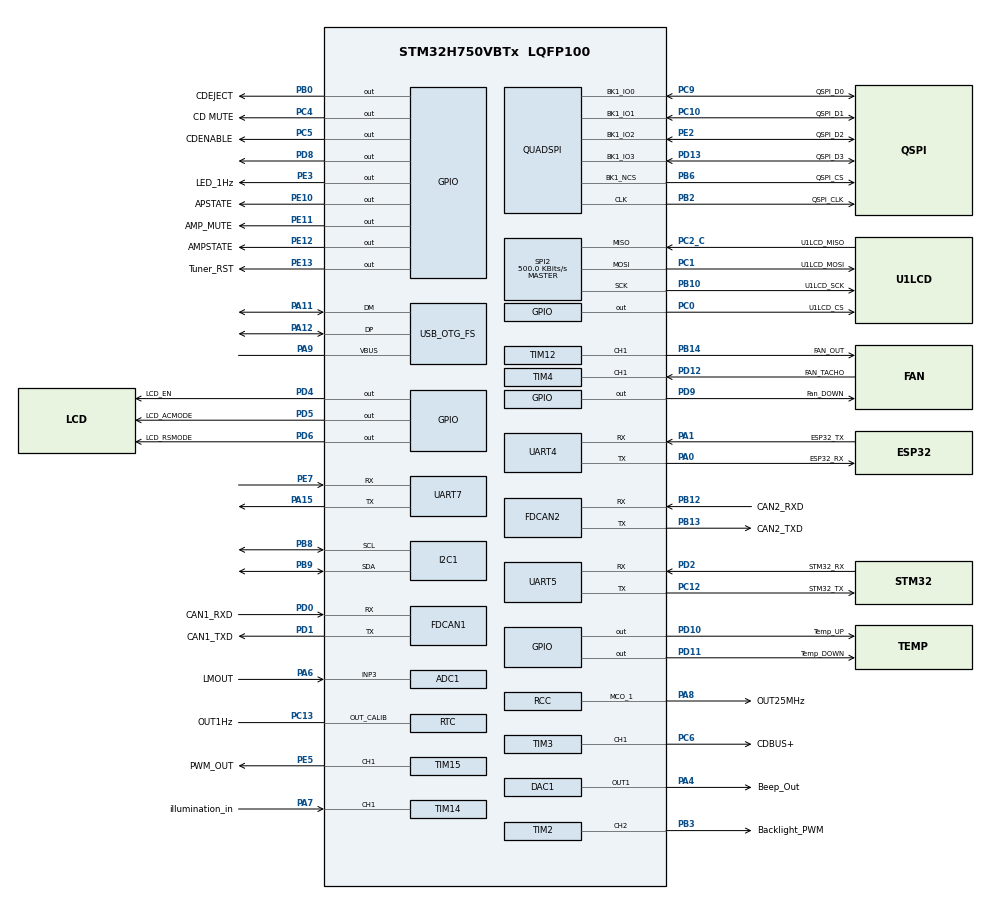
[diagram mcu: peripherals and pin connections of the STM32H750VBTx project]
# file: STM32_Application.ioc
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ADC1.Channel-1\#ChannelRegularConversion=ADC_CHANNEL_3
ADC1.NbrOfConversionFlag=1
ADC1.OffsetNumber-1\#ChannelRegularConversion=ADC_OFFSET_NONE
ADC1.OffsetSignedSaturation-1\#ChannelRegularConversion=DISABLE
ADC1.Rank-1\#ChannelRegularConversion=1
ADC1.SamplingTime-1\#ChannelRegularConversion=ADC_SAMPLETIME_1CYCLE_5
ADC1.master=1
CORTEX_M7.default_mode_Activation=1
DAC1.DAC_Channel-DAC_OUT1=DAC_CHANNEL_1
Dma.Request0=UART4_RX
Dma.Request1=UART5_RX
Dma.Request2=UART7_RX
Dma.UART4_RX.0.Direction=DMA_PERIPH_TO_MEMORY
Dma.UART4_RX.0.EventEnable=DISABLE
Dma.UART4_RX.0.FIFOMode=DMA_FIFOMODE_DISABLE
Dma.UART4_RX.0.Instance=DMA1_Stream0
Dma.UART4_RX.0.MemDataAlignment=DMA_MDATAALIGN_BYTE
Dma.UART4_RX.0.MemInc=DMA_MINC_ENABLE
Dma.UART4_RX.0.Mode=DMA_NORMAL
Dma.UART4_RX.0.PeriphDataAlignment=DMA_PDATAALIGN_BYTE
Dma.UART4_RX.0.PeriphInc=DMA_PINC_DISABLE
Dma.UART4_RX.0.Polarity=HAL_DMAMUX_REQ_GEN_RISING
Dma.UART4_RX.0.Priority=DMA_PRIORITY_LOW
Dma.UART4_RX.0.RequestNumber=1
Dma.UART4_RX.0.SignalID=NONE
Dma.UART4_RX.0.SyncEnable=DISABLE
Dma.UART4_RX.0.SyncPolarity=HAL_DMAMUX_SYNC_NO_EVENT
Dma.UART4_RX.0.SyncRequestNumber=1
Dma.UART4_RX.0.SyncSignalID=NONE
Dma.UART5_RX.1.Direction=DMA_PERIPH_TO_MEMORY
Dma.UART5_RX.1.EventEnable=DISABLE
Dma.UART5_RX.1.FIFOMode=DMA_FIFOMODE_DISABLE
Dma.UART5_RX.1.Instance=DMA1_Stream1
Dma.UART5_RX.1.MemDataAlignment=DMA_MDATAALIGN_BYTE
Dma.UART5_RX.1.MemInc=DMA_MINC_ENABLE
Dma.UART5_RX.1.Mode=DMA_NORMAL
Dma.UART5_RX.1.PeriphDataAlignment=DMA_PDATAALIGN_BYTE
Dma.UART5_RX.1.PeriphInc=DMA_PINC_DISABLE
Dma.UART5_RX.1.Polarity=HAL_DMAMUX_REQ_GEN_RISING
Dma.UART5_RX.1.Priority=DMA_PRIORITY_LOW
Dma.UART5_RX.1.RequestNumber=1
Dma.UART5_RX.1.SignalID=NONE
Dma.UART5_RX.1.SyncEnable=DISABLE
Dma.UART5_RX.1.SyncPolarity=HAL_DMAMUX_SYNC_NO_EVENT
Dma.UART5_RX.1.SyncRequestNumber=1
Dma.UART5_RX.1.SyncSignalID=NONE
Dma.UART7_RX.2.Direction=DMA_PERIPH_TO_MEMORY
Dma.UART7_RX.2.EventEnable=DISABLE
Dma.UART7_RX.2.FIFOMode=DMA_FIFOMODE_DISABLE
Dma.UART7_RX.2.Instance=DMA1_Stream2
Dma.UART7_RX.2.MemDataAlignment=DMA_MDATAALIGN_BYTE
Dma.UART7_RX.2.MemInc=DMA_MINC_ENABLE
Dma.UART7_RX.2.Mode=DMA_NORMAL
Dma.UART7_RX.2.PeriphDataAlignment=DMA_PDATAALIGN_BYTE
Dma.UART7_RX.2.PeriphInc=DMA_PINC_DISABLE
Dma.UART7_RX.2.Polarity=HAL_DMAMUX_REQ_GEN_RISING
Dma.UART7_RX.2.Priority=DMA_PRIORITY_LOW
Dma.UART7_RX.2.RequestNumber=1
Dma.UART7_RX.2.SignalID=NONE
Dma.UART7_RX.2.SyncEnable=DISABLE
Dma.UART7_RX.2.SyncPolarity=HAL_DMAMUX_SYNC_NO_EVENT
Dma.UART7_RX.2.SyncRequestNumber=1
Dma.UART7_RX.2.SyncSignalID=NONE
FDCAN1.CalculateBaudRateNominal=500000
FDCAN1.CalculateTimeBitNominal=2000
FDCAN1.CalculateTimeQuantumNominal=200.0
FDCAN1.NominalPrescaler=5
FDCAN1.NominalTimeSeg1=7
FDCAN1.NominalTimeSeg2=2
FDCAN1.TxFifoQueueElmtsNbr=32
FDCAN2.CalculateBaudRateNominal=500000
FDCAN2.CalculateTimeBitNominal=2000
FDCAN2.CalculateTimeQuantumNominal=200.0
FDCAN2.NominalPrescaler=5
FDCAN2.NominalTimeSeg1=7
FDCAN2.NominalTimeSeg2=2
FDCAN2.TxFifoQueueElmtsNbr=32
I2C1.Timing=0x00C0EAFF
Mcu.Family=STM32H7
Mcu.Name=STM32H750VBTx
Mcu.Package=LQFP100
NVIC.DMA1_Stream0_IRQn=true\:0\:0\:false\:false\:true\:false\:true\:true
NVIC.DMA1_Stream1_IRQn=true\:0\:0\:false\:false\:true\:false\:true\:true
NVIC.DMA1_Stream2_IRQn=true\:0\:0\:false\:false\:true\:false\:true\:true
NVIC.OTG_FS_IRQn=true\:0\:0\:false\:false\:true\:false\:true\:true
NVIC.PriorityGroup=NVIC_PRIORITYGROUP_4
NVIC.TIM3_IRQn=true\:0\:0\:false\:false\:true\:true\:true\:true
NVIC.UART4_IRQn=true\:0\:0\:false\:false\:true\:true\:true\:true
NVIC.UART7_IRQn=true\:0\:0\:false\:false\:true\:true\:true\:true
PA0.GPIO_Label=ESP32_RX
PA0.Mode=Asynchronous
PA0.Signal=UART4_TX
PA1.GPIO_Label=ESP32_TX
PA1.Mode=Asynchronous
PA1.Signal=UART4_RX
PA11.Mode=Device_Only
PA11.PinAttribute=Free
PA11.Signal=USB_OTG_FS_DM
PA12.Mode=Device_Only
PA12.PinAttribute=Free
PA12.Signal=USB_OTG_FS_DP
PA13\ (JTMS/SWDIO).Mode=Serial_Wire
PA13\ (JTMS/SWDIO).Signal=DEBUG_JTMS-SWDIO
PA14\ (JTCK/SWCLK).Mode=Serial_Wire
PA14\ (JTCK/SWCLK).Signal=DEBUG_JTCK-SWCLK
PA15\ (JTDI).Mode=Asynchronous
PA15\ (JTDI).PinAttribute=Free
PA15\ (JTDI).Signal=UART7_TX
PA4.GPIO_Label=Beep_Out
PA4.Signal=COMP_DAC11_group
PA6.GPIO_Label=LMOUT
PA6.Signal=ADCx_INP3
PA7.GPIO_Label=illumination_in
PA7.PinAttribute=Free
PA7.Signal=S_TIM14_CH1
PA8.GPIO_Label=OUT25MHz
PA8.Mode=Clock-out-1
PA8.PinAttribute=Free
PA8.Signal=RCC_MCO_1
PA9.Mode=Activate_VBUS
PA9.PinAttribute=Free
PA9.Signal=USB_OTG_FS_VBUS
PB0.GPIO_Label=CDEJECT
PB0.PinAttribute=Free
PB0.Signal=GPIO_Output
PB10.GPIO_Label=U1LCD_SCK
PB10.Mode=Full_Duplex_Master
PB10.Signal=SPI2_SCK
PB12.GPIO_Label=CAN2_RXD
PB12.Mode=FDCAN_Activate
PB12.Signal=FDCAN2_RX
PB13.GPIO_Label=CAN2_TXD
PB13.Mode=FDCAN_Activate
PB13.Signal=FDCAN2_TX
PB14.GPIO_Label=FAN_OUT
PB14.Signal=S_TIM12_CH1
PB2.GPIO_Label=QSPI_CLK
PB2.Mode=Single Bank 1
PB2.PinAttribute=Free
PB2.Signal=QUADSPI_CLK
PB3\ (JTDO/TRACESWO).GPIO_Label=Backlight_PWM
PB3\ (JTDO/TRACESWO).PinAttribute=Free
PB3\ (JTDO/TRACESWO).Signal=S_TIM2_CH2
PB6.GPIO_Label=QSPI_CS
PB6.Mode=Single Bank 1
PB6.Signal=QUADSPI_BK1_NCS
PB8.Mode=I2C
PB8.Signal=I2C1_SCL
PB9.Mode=I2C
PB9.Signal=I2C1_SDA
PC0.GPIO_Label=U1LCD_CS
PC0.Signal=GPIO_Output
PC1.GPIO_Label=U1LCD_MOSI
PC1.Mode=Full_Duplex_Master
PC1.Signal=SPI2_MOSI
PC10.GPIO_Label=QSPI_D1
PC10.Mode=Single Bank 1
PC10.PinAttribute=Free
PC10.Signal=QUADSPI_BK1_IO1
PC12.GPIO_Label=STM32_TX
PC12.Mode=Asynchronous
PC12.PinAttribute=Free
PC12.Signal=UART5_TX
PC13.GPIO_Label=OUT1Hz
PC13.Mode=Calibration_1Hz
PC13.Signal=RTC_OUT_CALIB
PC14-OSC32_IN\ (OSC32_IN).Mode=LSE-External-Oscillator
PC14-OSC32_IN\ (OSC32_IN).Signal=RCC_OSC32_IN
PC15-OSC32_OUT\ (OSC32_OUT).Mode=LSE-External-Oscillator
PC15-OSC32_OUT\ (OSC32_OUT).Signal=RCC_OSC32_OUT
PC2_C.GPIO_Label=U1LCD_MISO
PC2_C.Mode=Full_Duplex_Master
PC2_C.Signal=SPI2_MISO
PC3_C.GPIO_Label=WheelButtonIN
PC3_C.Signal=ADC3_INP1
PC4.GPIO_Label=CD MUTE
PC4.PinAttribute=Free
PC4.Signal=GPIO_Output
PC5.GPIO_Label=CDENABLE
PC5.PinAttribute=Free
PC5.Signal=GPIO_Output
PC6.GPIO_Label=CDBUS+
PC6.Signal=S_TIM3_CH1
PC9.GPIO_Label=QSPI_D0
PC9.Mode=Single Bank 1
PC9.Signal=QUADSPI_BK1_IO0
PD0.GPIO_Label=CAN1_RXD
PD0.Mode=FDCAN_Activate
PD0.PinAttribute=Free
PD0.Signal=FDCAN1_RX
PD1.GPIO_Label=CAN1_TXD
PD1.Mode=FDCAN_Activate
PD1.PinAttribute=Free
PD1.Signal=FDCAN1_TX
PD10.GPIO_Label=Temp_UP
PD10.Signal=GPIO_Output
PD11.GPIO_Label=Temp_DOWN
PD11.Signal=GPIO_Output
PD12.GPIO_Label=FAN_TACHO
PD12.Signal=S_TIM4_CH1
PD13.GPIO_Label=QSPI_D3
PD13.Mode=Single Bank 1
PD13.Signal=QUADSPI_BK1_IO3
PD2.GPIO_Label=STM32_RX
PD2.Mode=Asynchronous
PD2.PinAttribute=Free
PD2.Signal=UART5_RX
PD4.GPIO_Label=LCD_EN
PD4.PinAttribute=Free
PD4.Signal=GPIO_Output
PD5.GPIO_Label=LCD_ACMODE
PD5.PinAttribute=Free
PD5.Signal=GPIO_Output
PD6.GPIO_Label=LCD_RSMODE
PD6.PinAttribute=Free
PD6.Signal=GPIO_Output
PD8.Signal=GPIO_Output
PD9.GPIO_Label=Fan_DOWN
PD9.Signal=GPIO_Output
PE10.GPIO_Label=APSTATE
PE10.Signal=GPIO_Output
PE11.GPIO_Label=AMP_MUTE
PE11.Signal=GPIO_Output
PE12.GPIO_Label=AMPSTATE
PE12.Signal=GPIO_Output
PE13.GPIO_Label=Tuner_RST
PE13.Signal=GPIO_Output
PE2.GPIO_Label=QSPI_D2
PE2.Mode=Single Bank 1
PE2.Signal=QUADSPI_BK1_IO2
PE3.GPIO_Label=LED_1Hz
PE3.Signal=GPIO_Output
PE5.GPIO_Label=PWM_OUT
PE5.Signal=S_TIM15_CH1
PE7.Mode=Asynchronous
PE7.Signal=UART7_RX
PH0-OSC_IN\ (PH0).Mode=HSE-External-Oscillator
PH0-OSC_IN\ (PH0).Signal=RCC_OSC_IN
PH1-OSC_OUT\ (PH1).Mode=HSE-External-Oscillator
PH1-OSC_OUT\ (PH1).Signal=RCC_OSC_OUT
ProjectManager.HeapSize=0x200
ProjectManager.StackSize=0x400
ProjectManager.TargetToolchain=STM32CubeIDE
RCC.ADCFreq_Value=75000000
RCC.APB1Freq_Value=50000000
RCC.APB2Freq_Value=100000000
RCC.APB3Freq_Value=100000000
RCC.APB4Freq_Value=100000000
RCC.CortexFreq_Value=400000000
RCC.D1PPRE=RCC_APB3_DIV2
RCC.D2PPRE1=RCC_APB1_DIV4
RCC.D2PPRE2=RCC_APB2_DIV2
RCC.D3PPRE=RCC_APB4_DIV2
RCC.DIVM1=2
RCC.DIVM2=2
RCC.DIVN1=64
RCC.DIVN2=12
RCC.DIVQ1=3
RCC.EnbaleCSS=false
RCC.FDCANCLockSelection=RCC_FDCANCLKSOURCE_HSE
RCC.FLatency-AdvancedSettings=FLASH_LATENCY_0
RCC.HCLKFreq_Value=200000000
RCC.HPRE=RCC_HCLK_DIV2
RCC.PLL1_VCI_Range-AdvancedSettings=RCC_PLL1VCIRANGE_0
RCC.PLL1_VCO_SEL-AdvancedSettings=RCC_PLL1VCOMEDIUM
RCC.PLL2FRACN=0
RCC.PLL2_VCI_Range-AdvancedSettings=RCC_PLL2VCIRANGE_0
RCC.PLL2_VCO_SEL-AdvancedSettings=RCC_PLL2VCOWIDE
RCC.PLL3FRACN=0
RCC.PLL3_VCI_Range-AdvancedSettings=RCC_PLL3VCIRANGE_0
RCC.PLL3_VCO_SEL-AdvancedSettings=RCC_PLL3VCOMEDIUM
RCC.PLLFRACN=0
RCC.PLLSourceVirtual=RCC_PLLSOURCE_HSE
RCC.PWR_Regulator_Voltage_Scale=PWR_REGULATOR_VOLTAGE_SCALE1
RCC.QSPICLockSelection=RCC_QSPICLKSOURCE_PLL2
RCC.SPI123CLockSelection=RCC_SPI123CLKSOURCE_CLKP
RCC.SYSCLKFreq_VALUE=400000000
RCC.SYSCLKSource=RCC_SYSCLKSOURCE_PLLCLK
RCC.Tim2Mul=1
RCC.USBCLockSelection=RCC_USBCLKSOURCE_HSI48
RCC.USBFreq_Value=48000000
SH.ADCx_INP3.0=ADC2_INP3
SH.ADCx_INP3.1=ADC1_INP3,IN3-Single-Ended
SH.COMP_DAC11_group.0=DAC1_OUT1,DAC_OUT1
SH.S_TIM12_CH1.0=TIM12_CH1,PWM Generation1 CH1
SH.S_TIM14_CH1.0=TIM14_CH1,Input_Capture1_from_TI1
SH.S_TIM15_CH1.0=TIM15_CH1,PWM Generation1 CH1
SH.S_TIM2_CH2.0=TIM2_CH2,PWM Generation2 CH2
SH.S_TIM3_CH1.0=TIM3_CH1,Output Compare1 CH1
SH.S_TIM4_CH1.0=TIM4_CH1,Input_Capture1_from_TI1
SPI2.BaudRatePrescaler=SPI_BAUDRATEPRESCALER_128
SPI2.CLKPhase=SPI_PHASE_2EDGE
SPI2.CLKPolarity=SPI_POLARITY_HIGH
SPI2.CalculateBaudRate=500.0 KBits/s
SPI2.Direction=SPI_DIRECTION_2LINES
SPI2.Mode=SPI_MODE_MASTER
SPI2.NSSPMode=SPI_NSS_PULSE_DISABLE
SPI2.VirtualType=VM_MASTER
TIM12.Channel-PWM\ Generation1\ CH1=TIM_CHANNEL_1
TIM14.Channel=TIM_CHANNEL_1
TIM15.Channel-PWM\ Generation1\ CH1=TIM_CHANNEL_1
TIM2.Channel-PWM\ Generation2\ CH2=TIM_CHANNEL_2
TIM3.AutoReloadPreload=TIM_AUTORELOAD_PRELOAD_ENABLE
TIM3.Channel-Output\ Compare1\ CH1=TIM_CHANNEL_1
TIM3.OC1Preload=ENABLE
TIM3.OCMode_1=TIM_OCMODE_ACTIVE
TIM4.Channel-Input_Capture1_from_TI1=TIM_CHANNEL_1
TIM6.TIM_MasterOutputTrigger=TIM_TRGO_UPDATE
USB_DEVICE.CLASS_NAME_FS=CDC
USB_DEVICE.VirtualMode-CDC_FS=Cdc
USB_DEVICE.VirtualModeFS=Cdc_FS
USB_OTG_FS.VirtualMode=Device_Only
VP_MEMORYMAP_VS_MEMORYMAP.Mode=CurAppReg
VP_RTC_VS_RTC_Activate.Mode=RTC_Enabled
VP_TIM12_VS_ClockSourceINT.Mode=Internal
VP_TIM14_VS_ClockSourceINT.Mode=Enable_Timer
VP_TIM15_VS_ClockSourceINT.Mode=Internal
VP_TIM2_VS_ClockSourceINT.Mode=Internal
VP_TIM4_VS_ClockSourceINT.Mode=Internal
VP_TIM6_VS_ClockSourceINT.Mode=Enable_Timer
VP_USB_DEVICE_VS_USB_DEVICE_CDC_FS.Mode=CDC_FS
board=custom

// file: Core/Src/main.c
/* USER CODE BEGIN Header */
/**
  ******************************************************************************
  * @file           : main.c
  * @brief          : Main program body
  ******************************************************************************
  * @attention
  *
  * Copyright (c) 2026 STMicroelectronics.
  * All rights reserved.
  *
  * This software is licensed under terms that can be found in the LICENSE file
  * in the root directory of this software component.
  * If no LICENSE file comes with this software, it is provided AS-IS.
  *
  ******************************************************************************
  */
/* USER CODE END Header */
#include "main.h"
#include "usb_device.h"

/* USER CODE BEGIN Includes */
#include <string.h>
#include "usbd_cdc_if.h"

//Communication folder
#include "communication/protocol.h"
#include "communication/canbus.h"
#include "communication/lcd.h"
#include "communication/climate.h"

//drivers folder
#include "drivers/lm75.h"
#include "drivers/si4703.h"
#include "drivers/tda7719.h"

//vehicle folder
#include "vehicle/audio.h"
#include "vehicle/time.h"
#include "vehicle/lighting.h"

/* USER CODE END Includes */

ADC_HandleTypeDef hadc1;

DAC_HandleTypeDef hdac1;

FDCAN_HandleTypeDef hfdcan1;
FDCAN_HandleTypeDef hfdcan2;

I2C_HandleTypeDef hi2c1;

QSPI_HandleTypeDef hqspi;

RTC_HandleTypeDef hrtc;

SPI_HandleTypeDef hspi2;

TIM_HandleTypeDef htim2;
TIM_HandleTypeDef htim3;
TIM_HandleTypeDef htim4;
TIM_HandleTypeDef htim6;
TIM_HandleTypeDef htim12;
TIM_HandleTypeDef htim14;
TIM_HandleTypeDef htim15;

UART_HandleTypeDef huart4;
UART_HandleTypeDef huart5;
UART_HandleTypeDef huart7;
DMA_HandleTypeDef hdma_uart4_rx;
DMA_HandleTypeDef hdma_uart5_rx;
DMA_HandleTypeDef hdma_uart7_rx;

/* USER CODE BEGIN PV */
uint32_t lastClimateSend = 0;
uint32_t lastFanSend = 0;
volatile uint8_t uart7ErrorFlag = 0;
volatile uint32_t uart7ErrorCode = 0;
int uart7RxCount = 0;

int uart5RxCount = 0;
uint32_t uart7LastSize;
RTC_TimeTypeDef sTime = {0};
RTC_DateTypeDef sDate = {0};
uint8_t lastMinute = 60; //not possible
volatile uint8_t minuteChanged = 1; // Start at 1 to update LCD on boot
uint8_t volumePending = 0;
uint8_t lastVolume = 0;
uint8_t volumeChange = 0;
uint8_t lcdReset = 0;
uint32_t lcdResetTimer = 0;
char lastLCDMessage[13] = "Welcome :)   "; //Init to welcome as standard
extern char lcdBuf[13];
extern ACState_t acState;
/* USER CODE END PV */

void SystemClock_Config(void);
void PeriphCommonClock_Config(void);
static void MPU_Config(void);
static void MX_GPIO_Init(void);
static void MX_DMA_Init(void);
static void MX_ADC1_Init(void);
static void MX_DAC1_Init(void);
static void MX_FDCAN1_Init(void);
static void MX_FDCAN2_Init(void);
static void MX_RTC_Init(void);
static void MX_SPI2_Init(void);
static void MX_TIM2_Init(void);
static void MX_TIM6_Init(void);
static void MX_TIM15_Init(void);
static void MX_UART4_Init(void);
static void MX_UART5_Init(void);
static void MX_UART7_Init(void);
static void MX_TIM4_Init(void);
static void MX_TIM12_Init(void);
static void MX_QUADSPI_Init(void);
static void MX_TIM14_Init(void);
static void MX_TIM3_Init(void);
static void MX_I2C1_Init(void);
/* USER CODE BEGIN PFP */
void Report_USB(const char* text);
void I2C_Scan(I2C_HandleTypeDef *hi2c);
void Startup_Handshake();
/* USER CODE END PFP */

int main(void)
{

  /* USER CODE BEGIN 1 */
	uint32_t pre_P1R = RTC->BKP1R;

  /* USER CODE END 1 */

  /* MPU Configuration--------------------------------------------------------*/
  MPU_Config();

  /* MCU Configuration--------------------------------------------------------*/

  /* Reset of all peripherals, Initializes the Flash interface and the Systick. */
  HAL_Init();

  /* Configure the system clock */
  SystemClock_Config();

  /* Configure the peripherals common clocks */
  PeriphCommonClock_Config();

  /* Initialize all configured peripherals */
  MX_GPIO_Init();
  MX_DMA_Init();
  MX_ADC1_Init();
  MX_DAC1_Init();
  MX_FDCAN1_Init();
  MX_FDCAN2_Init();
  MX_RTC_Init();
  MX_SPI2_Init();
  MX_TIM2_Init();
  MX_TIM6_Init();
  MX_TIM15_Init();
  MX_UART4_Init();
  MX_UART5_Init();
  MX_UART7_Init();
  MX_USB_DEVICE_Init();
  MX_TIM4_Init();
  MX_TIM12_Init();
  MX_QUADSPI_Init();
  MX_TIM14_Init();
  MX_TIM3_Init();
  MX_I2C1_Init();

  HAL_PWR_EnableBkUpAccess();
  char buf[240];
  if (pre_P1R == 0x0000){
	  snprintf(buf, sizeof(buf),
		  "COLD: TR=0x%08lX DR=0x%08lX BKP1=0x%08lX BKP1_R=0x%08lX BDCR=0x%08lX BKP1R=0x%08lX BKP0R=0x%08lX",
		  RTC->TR, RTC->DR, RTC->BKP1R, pre_P1R, RCC->BDCR,  RTC->BKP1R, RTC->BKP0R);
  }
  else{
	  snprintf(buf, sizeof(buf),
		  "HOT: TR=0x%08lX DR=0x%08lX BKP1=0x%08lX BKP1_R=0x%08lX BDCR=0x%08lX BKP1R=0x%08lX BKP0R=0x%08lX",
		  RTC->TR, RTC->DR, RTC->BKP1R, pre_P1R, RCC->BDCR,  RTC->BKP1R, RTC->BKP0R);
  }
  HAL_Delay(1000);
  DWT_Init();
  TDA7719_Init(&hi2c1);
  //Report_USB("Booting...");
  LCD_Init(&hspi2, &htim2);
  Climate_Init(&huart7);
  LCD_Print("Booting...");

  CAN_Start(&hfdcan1, &hfdcan2);

  HAL_UARTEx_ReceiveToIdle_DMA(&huart4, RxBuf4, RX_PACKET_LEN);
  HAL_UARTEx_ReceiveToIdle_DMA(&huart5, RxBuf5, RX_PACKET_LEN);
  //Protocol_Send(&huart4, STM, CMD_HANDSHAKE, NULL, 0);
  Startup_Handshake();

  //Climate_SendStatus(&huart5);
  //HAL_Delay(1000);

  //LM75_Init(&hi2c2);
  // Basic temperature read
  //float temp = LM75_ReadTemp();

  /* USER CODE END 2 */

  /* Infinite loop */
  /* USER CODE BEGIN WHILE */
  //I2C_Scan(&hi2c1);
  int counter = 0;
  int lastCANsend = HAL_GetTick();
  uint32_t lastPrint = 0;

  Audio_Init();
  LCD_Print("Loop Starting...");
  HAL_Delay(100);
  Report_USB(buf);
  HAL_Delay(1000);

  while (1)
  {
      counter++;
      Protocol_CheckFlag(&huart4, &huart5);
      Climate_CheckFlag();
      CAN_CheckFlag();

      HAL_RTC_GetTime(&hrtc, &sTime, RTC_FORMAT_BIN);
      HAL_RTC_GetDate(&hrtc, &sDate, RTC_FORMAT_BIN); // CRITICAL: You MUST read the date after the time

      if (sTime.Minutes != lastMinute) {
    	  Report_USB("Minute Changed");
          Climate_SetLCD(&acState);
          lastMinute = sTime.Minutes; // Save the new minute
      }

      if (lcdReset && (HAL_GetTick() - lcdResetTimer >= 3000)){
			  //reset LCD to the last known buffer
			  LCD_Print(lastLCDMessage);
			  lcdReset = 0;
      }

      if (HAL_GetTick() - lastCANsend >= 1000) {
    	  //Send CAN frame every second to test CAN2.
          uint8_t data[8] = {0x11, 0x22, 0x33, 0x44, 0x55, 0x66, 0x77, 0x88};
          CAN_Send(data, 0x123);

          FDCAN_ProtocolStatusTypeDef psr;
          HAL_FDCAN_GetProtocolStatus(&hfdcan2, &psr);

          char dbg[128];
          lastCANsend = HAL_GetTick();
          FDCAN_ProtocolStatusTypeDef psr1;
          HAL_FDCAN_GetProtocolStatus(&hfdcan1, &psr1);
      }

      if (HAL_GetTick() - lastPrint > 20)
      {
          lastPrint = HAL_GetTick();
          Climate_SendDefault();
      }

  }
      /* USER CODE END WHILE */

}
    /* Use this when LSE is working...
     *
     */
    void SystemClock_Config(void)
    {
      RCC_OscInitTypeDef RCC_OscInitStruct = {0};
      RCC_ClkInitTypeDef RCC_ClkInitStruct = {0};

      // Supply configuration update enable
      HAL_PWREx_ConfigSupply(PWR_LDO_SUPPLY);

      // Configure the main internal regulator output voltage
      __HAL_PWR_VOLTAGESCALING_CONFIG(PWR_REGULATOR_VOLTAGE_SCALE1);

      while(!__HAL_PWR_GET_FLAG(PWR_FLAG_VOSRDY)) {}

      // Configure LSE Drive Capability
      HAL_PWR_EnableBkUpAccess();

	// *** TEMPORARY CODE TO CLEAR STUCK LSI SETTING ***
	//__HAL_RCC_BACKUPRESET_FORCE();
	//__HAL_RCC_BACKUPRESET_RELEASE();
	// *************************************************

      __HAL_RCC_LSEDRIVE_CONFIG(RCC_LSEDRIVE_HIGH);

      // Initializes the RCC Oscillators according to the specified parameters
      //in the RCC_OscInitTypeDef structure.

      RCC_OscInitStruct.OscillatorType = RCC_OSCILLATORTYPE_HSI48|RCC_OSCILLATORTYPE_HSI
                                  |RCC_OSCILLATORTYPE_HSE|RCC_OSCILLATORTYPE_LSE;
      RCC_OscInitStruct.HSEState = RCC_HSE_ON;
      RCC_OscInitStruct.LSEState = RCC_LSE_ON;
      RCC_OscInitStruct.HSIState = RCC_HSI_DIV1;
      RCC_OscInitStruct.HSICalibrationValue = RCC_HSICALIBRATION_DEFAULT;
      RCC_OscInitStruct.HSI48State = RCC_HSI48_ON;
      RCC_OscInitStruct.PLL.PLLState = RCC_PLL_ON;
      RCC_OscInitStruct.PLL.PLLSource = RCC_PLLSOURCE_HSE;
      RCC_OscInitStruct.PLL.PLLM = 2;
      RCC_OscInitStruct.PLL.PLLN = 64;
      RCC_OscInitStruct.PLL.PLLP = 2;
      RCC_OscInitStruct.PLL.PLLQ = 3;
      RCC_OscInitStruct.PLL.PLLR = 2;
      RCC_OscInitStruct.PLL.PLLRGE = RCC_PLL1VCIRANGE_3;
      RCC_OscInitStruct.PLL.PLLVCOSEL = RCC_PLL1VCOWIDE;
      RCC_OscInitStruct.PLL.PLLFRACN = 0;
      if (HAL_RCC_OscConfig(&RCC_OscInitStruct) != HAL_OK)
      {
        Error_Handler();
      }

      if (__HAL_RCC_GET_FLAG(RCC_FLAG_LSERDY) == RESET) {
          uint32_t timeout = HAL_GetTick();
          while (__HAL_RCC_GET_FLAG(RCC_FLAG_LSERDY) == RESET) {
              if (HAL_GetTick() - timeout > 2000) {
                  Error_Handler(); // or fallback to LSI
              }
          }
      }

      // Initializes the CPU, AHB and APB buses clocks

      RCC_ClkInitStruct.ClockType = RCC_CLOCKTYPE_HCLK|RCC_CLOCKTYPE_SYSCLK
                                  |RCC_CLOCKTYPE_PCLK1|RCC_CLOCKTYPE_PCLK2
                                  |RCC_CLOCKTYPE_D3PCLK1|RCC_CLOCKTYPE_D1PCLK1;
      RCC_ClkInitStruct.SYSCLKSource = RCC_SYSCLKSOURCE_PLLCLK;
      RCC_ClkInitStruct.SYSCLKDivider = RCC_SYSCLK_DIV1;
      RCC_ClkInitStruct.AHBCLKDivider = RCC_HCLK_DIV2;
      RCC_ClkInitStruct.APB3CLKDivider = RCC_APB3_DIV2;
      RCC_ClkInitStruct.APB1CLKDivider = RCC_APB1_DIV4;
      RCC_ClkInitStruct.APB2CLKDivider = RCC_APB2_DIV2;
      RCC_ClkInitStruct.APB4CLKDivider = RCC_APB4_DIV2;

      RCC_PeriphCLKInitTypeDef PeriphClkInitStruct = {0};

      if (HAL_RCC_ClockConfig(&RCC_ClkInitStruct, FLASH_LATENCY_2) != HAL_OK)
      {
        Error_Handler();
      }

      // Route the LSE to the RTC block
      PeriphClkInitStruct.PeriphClockSelection = RCC_PERIPHCLK_RTC;
      PeriphClkInitStruct.RTCClockSelection = RCC_RTCCLKSOURCE_LSE;
      if (HAL_RCCEx_PeriphCLKConfig(&PeriphClkInitStruct) != HAL_OK)
      {
        Error_Handler();
      }

      HAL_RCC_MCOConfig(RCC_MCO1, RCC_MCO1SOURCE_LSE, RCC_MCODIV_1);
      //Change to HSE for 25MHz
  }

void PeriphCommonClock_Config(void)
{
  RCC_PeriphCLKInitTypeDef PeriphClkInitStruct = {0};

  /** Initializes the peripherals clock
  */
  PeriphClkInitStruct.PeriphClockSelection = RCC_PERIPHCLK_QSPI|RCC_PERIPHCLK_ADC
                              |RCC_PERIPHCLK_CKPER;
  PeriphClkInitStruct.PLL2.PLL2M = 2;
  PeriphClkInitStruct.PLL2.PLL2N = 12;
  PeriphClkInitStruct.PLL2.PLL2P = 2;
  PeriphClkInitStruct.PLL2.PLL2Q = 2;
  PeriphClkInitStruct.PLL2.PLL2R = 2;
  PeriphClkInitStruct.PLL2.PLL2RGE = RCC_PLL2VCIRANGE_3;
  PeriphClkInitStruct.PLL2.PLL2VCOSEL = RCC_PLL2VCOMEDIUM;
  PeriphClkInitStruct.PLL2.PLL2FRACN = 0;
  PeriphClkInitStruct.QspiClockSelection = RCC_QSPICLKSOURCE_PLL2;
  PeriphClkInitStruct.CkperClockSelection = RCC_CLKPSOURCE_HSI;
  PeriphClkInitStruct.AdcClockSelection = RCC_ADCCLKSOURCE_PLL2;
  if (HAL_RCCEx_PeriphCLKConfig(&PeriphClkInitStruct) != HAL_OK)
  {
    Error_Handler();
  }
}

static void MX_ADC1_Init(void)
{

  ADC_MultiModeTypeDef multimode = {0};
  ADC_ChannelConfTypeDef sConfig = {0};

  /** Common config
  */
  hadc1.Instance = ADC1;
  hadc1.Init.ClockPrescaler = ADC_CLOCK_ASYNC_DIV1;
  hadc1.Init.Resolution = ADC_RESOLUTION_16B;
  hadc1.Init.ScanConvMode = ADC_SCAN_DISABLE;
  hadc1.Init.EOCSelection = ADC_EOC_SINGLE_CONV;
  hadc1.Init.LowPowerAutoWait = DISABLE;
  hadc1.Init.ContinuousConvMode = DISABLE;
  hadc1.Init.NbrOfConversion = 1;
  hadc1.Init.DiscontinuousConvMode = DISABLE;
  hadc1.Init.ExternalTrigConv = ADC_SOFTWARE_START;
  hadc1.Init.ExternalTrigConvEdge = ADC_EXTERNALTRIGCONVEDGE_NONE;
  hadc1.Init.ConversionDataManagement = ADC_CONVERSIONDATA_DR;
  hadc1.Init.Overrun = ADC_OVR_DATA_PRESERVED;
  hadc1.Init.LeftBitShift = ADC_LEFTBITSHIFT_NONE;
  hadc1.Init.OversamplingMode = DISABLE;
  hadc1.Init.Oversampling.Ratio = 1;
  if (HAL_ADC_Init(&hadc1) != HAL_OK)
  {
    Error_Handler();
  }

  /** Configure the ADC multi-mode
  */
  multimode.Mode = ADC_MODE_INDEPENDENT;
  if (HAL_ADCEx_MultiModeConfigChannel(&hadc1, &multimode) != HAL_OK)
  {
    Error_Handler();
  }

  /** Configure Regular Channel
  */
  sConfig.Channel = ADC_CHANNEL_3;
  sConfig.Rank = ADC_REGULAR_RANK_1;
  sConfig.SamplingTime = ADC_SAMPLETIME_1CYCLE_5;
  sConfig.SingleDiff = ADC_SINGLE_ENDED;
  sConfig.OffsetNumber = ADC_OFFSET_NONE;
  sConfig.Offset = 0;
  sConfig.OffsetSignedSaturation = DISABLE;
  if (HAL_ADC_ConfigChannel(&hadc1, &sConfig) != HAL_OK)
  {
    Error_Handler();
  }

}

static void MX_DAC1_Init(void)
{

  DAC_ChannelConfTypeDef sConfig = {0};

  /** DAC Initialization
  */
  hdac1.Instance = DAC1;
  if (HAL_DAC_Init(&hdac1) != HAL_OK)
  {
    Error_Handler();
  }

  /** DAC channel OUT1 config
  */
  sConfig.DAC_SampleAndHold = DAC_SAMPLEANDHOLD_DISABLE;
  sConfig.DAC_Trigger = DAC_TRIGGER_NONE;
  sConfig.DAC_OutputBuffer = DAC_OUTPUTBUFFER_ENABLE;
  sConfig.DAC_ConnectOnChipPeripheral = DAC_CHIPCONNECT_DISABLE;
  sConfig.DAC_UserTrimming = DAC_TRIMMING_FACTORY;
  if (HAL_DAC_ConfigChannel(&hdac1, &sConfig, DAC_CHANNEL_1) != HAL_OK)
  {
    Error_Handler();
  }

}

static void MX_FDCAN1_Init(void)
{

  hfdcan1.Instance = FDCAN1;
  hfdcan1.Init.FrameFormat = FDCAN_FRAME_CLASSIC;
  hfdcan1.Init.Mode = FDCAN_MODE_NORMAL;
  hfdcan1.Init.AutoRetransmission = DISABLE;
  hfdcan1.Init.TransmitPause = DISABLE;
  hfdcan1.Init.ProtocolException = DISABLE;
  hfdcan1.Init.NominalPrescaler = 5;
  hfdcan1.Init.NominalSyncJumpWidth = 1;
  hfdcan1.Init.NominalTimeSeg1 = 7;
  hfdcan1.Init.NominalTimeSeg2 = 2;
  hfdcan1.Init.DataPrescaler = 1;
  hfdcan1.Init.DataSyncJumpWidth = 1;
  hfdcan1.Init.DataTimeSeg1 = 1;
  hfdcan1.Init.DataTimeSeg2 = 1;
  hfdcan1.Init.MessageRAMOffset = 0;
  hfdcan1.Init.StdFiltersNbr = 1;
  hfdcan1.Init.ExtFiltersNbr = 0;
  hfdcan1.Init.RxFifo0ElmtsNbr = 8;
  hfdcan1.Init.RxFifo0ElmtSize = FDCAN_DATA_BYTES_8;
  hfdcan1.Init.RxFifo1ElmtsNbr = 0;
  hfdcan1.Init.RxFifo1ElmtSize = FDCAN_DATA_BYTES_8;
  hfdcan1.Init.RxBuffersNbr = 8;
  hfdcan1.Init.RxBufferSize = FDCAN_DATA_BYTES_8;
  hfdcan1.Init.TxEventsNbr = 0;
  hfdcan1.Init.TxBuffersNbr = 0;
  hfdcan1.Init.TxFifoQueueElmtsNbr = 32;
  hfdcan1.Init.TxFifoQueueMode = FDCAN_TX_FIFO_OPERATION;
  hfdcan1.Init.TxElmtSize = FDCAN_DATA_BYTES_8;
  if (HAL_FDCAN_Init(&hfdcan1) != HAL_OK)
  {
    Error_Handler();
  }

}

static void MX_FDCAN2_Init(void)
{

  hfdcan2.Instance = FDCAN2;
  hfdcan2.Init.FrameFormat = FDCAN_FRAME_CLASSIC;
  hfdcan2.Init.Mode = FDCAN_MODE_NORMAL;
  hfdcan2.Init.AutoRetransmission = DISABLE;
  hfdcan2.Init.TransmitPause = DISABLE;
  hfdcan2.Init.ProtocolException = DISABLE;
  hfdcan2.Init.NominalPrescaler = 5;
  hfdcan2.Init.NominalSyncJumpWidth = 1;
  hfdcan2.Init.NominalTimeSeg1 = 7;
  hfdcan2.Init.NominalTimeSeg2 = 2;
  hfdcan2.Init.DataPrescaler = 1;
  hfdcan2.Init.DataSyncJumpWidth = 1;
  hfdcan2.Init.DataTimeSeg1 = 1;
  hfdcan2.Init.DataTimeSeg2 = 1;
  hfdcan2.Init.MessageRAMOffset = 193; //Avoid collisions with FDCAN1
  hfdcan2.Init.StdFiltersNbr = 0;
  hfdcan2.Init.ExtFiltersNbr = 0;
  hfdcan2.Init.RxFifo0ElmtsNbr = 8;
  hfdcan2.Init.RxFifo0ElmtSize = FDCAN_DATA_BYTES_8;
  hfdcan2.Init.RxFifo1ElmtsNbr = 0;
  hfdcan2.Init.RxFifo1ElmtSize = FDCAN_DATA_BYTES_8;
  hfdcan2.Init.RxBuffersNbr = 8;
  hfdcan2.Init.RxBufferSize = FDCAN_DATA_BYTES_8;
  hfdcan2.Init.TxEventsNbr = 0;
  hfdcan2.Init.TxBuffersNbr = 0;
  hfdcan2.Init.TxFifoQueueElmtsNbr = 32;
  hfdcan2.Init.TxFifoQueueMode = FDCAN_TX_FIFO_OPERATION;
  hfdcan2.Init.TxElmtSize = FDCAN_DATA_BYTES_8;

  if (HAL_FDCAN_Init(&hfdcan2) != HAL_OK)
  {
    Error_Handler();
  }

}

static void MX_I2C1_Init(void)
{

  hi2c1.Instance = I2C1;
  hi2c1.Init.Timing = 0x00C0EAFF;
  hi2c1.Init.OwnAddress1 = 0;
  hi2c1.Init.AddressingMode = I2C_ADDRESSINGMODE_7BIT;
  hi2c1.Init.DualAddressMode = I2C_DUALADDRESS_DISABLE;
  hi2c1.Init.OwnAddress2 = 0;
  hi2c1.Init.OwnAddress2Masks = I2C_OA2_NOMASK;
  hi2c1.Init.GeneralCallMode = I2C_GENERALCALL_DISABLE;
  hi2c1.Init.NoStretchMode = I2C_NOSTRETCH_DISABLE;
  if (HAL_I2C_Init(&hi2c1) != HAL_OK)
  {
    Error_Handler();
  }

  /** Configure Analogue filter
  */
  if (HAL_I2CEx_ConfigAnalogFilter(&hi2c1, I2C_ANALOGFILTER_ENABLE) != HAL_OK)
  {
    Error_Handler();
  }

  /** Configure Digital filter
  */
  if (HAL_I2CEx_ConfigDigitalFilter(&hi2c1, 0) != HAL_OK)
  {
    Error_Handler();
  }

}

static void MX_QUADSPI_Init(void)
{

  /* QUADSPI parameter configuration*/
  hqspi.Instance = QUADSPI;
  hqspi.Init.ClockPrescaler = 255;
  hqspi.Init.FifoThreshold = 1;
  hqspi.Init.SampleShifting = QSPI_SAMPLE_SHIFTING_NONE;
  hqspi.Init.FlashSize = 1;
  hqspi.Init.ChipSelectHighTime = QSPI_CS_HIGH_TIME_1_CYCLE;
  hqspi.Init.ClockMode = QSPI_CLOCK_MODE_0;
  hqspi.Init.FlashID = QSPI_FLASH_ID_1;
  hqspi.Init.DualFlash = QSPI_DUALFLASH_DISABLE;
  if (HAL_QSPI_Init(&hqspi) != HAL_OK)
  {
    Error_Handler();
  }

}

static void MX_RTC_Init(void)
{
  hrtc.Instance = RTC;
  hrtc.Init.HourFormat = RTC_HOURFORMAT_24;
  hrtc.Init.AsynchPrediv = 127;
  hrtc.Init.SynchPrediv = 255;
  hrtc.Init.OutPut = RTC_OUTPUT_DISABLE;
  hrtc.Init.OutPutPolarity = RTC_OUTPUT_POLARITY_HIGH;
  hrtc.Init.OutPutType = RTC_OUTPUT_TYPE_OPENDRAIN;
  hrtc.Init.OutPutRemap = RTC_OUTPUT_REMAP_NONE;

  HAL_PWR_EnableBkUpAccess();

  if (HAL_RTC_Init(&hrtc) != HAL_OK) {
      Error_Handler();
  }

  uint32_t magic = RTC->BKP1R;

  if (magic == 0x0000) {
      RTC_TimeTypeDef sTime = {0};
      RTC_DateTypeDef sDate = {0};

      sTime.Hours   = 12;
      sTime.Minutes = 0;
      sTime.Seconds = 45;

      sDate.Date  = 1;
      sDate.Month = 1;
      sDate.Year  = 26;

      HAL_RTC_SetTime(&hrtc, &sTime, RTC_FORMAT_BIN);
      HAL_RTC_SetDate(&hrtc, &sDate, RTC_FORMAT_BIN);
  }

  RTC->BKP1R = 0xCCCC0000;  // marker "cold"

  // Cold boot: full RTC initialisation.

  // Bypass shadow registers on cold boot too, so behaviour is consistent.
  //__HAL_RTC_WRITEPROTECTION_DISABLE(&hrtc);
  //SET_BIT(RTC->CR, RTC_CR_BYPSHAD);
  //__HAL_RTC_WRITEPROTECTION_ENABLE(&hrtc);

  if (HAL_RTCEx_SetCalibrationOutPut(&hrtc, RTC_CALIBOUTPUT_1HZ) != HAL_OK) {
      Error_Handler();
  }

  /*

  // In Protocol_ProcessPacket, case CMD_SET_TIME (0x15):
  // payload layout: [hours, minutes, seconds, day, month, year_lo, year_hi]
  RTC_TimeTypeDef sTime = {0};
  RTC_DateTypeDef sDate = {0};

  sTime.Hours   = 12;
  sTime.Minutes = 0;
  sTime.Seconds = 0;
  sTime.TimeFormat = RTC_HOURFORMAT12_AM;        // unused in 24h mode but init it
  sTime.DayLightSaving = RTC_DAYLIGHTSAVING_NONE;
  sTime.StoreOperation = RTC_STOREOPERATION_RESET;

  sDate.Date    = 1;
  sDate.Month   = 1;
  sDate.Year    = 26;                 // 0–99, year offset from 2000
  sDate.WeekDay = RTC_WEEKDAY_THURSDAY;            // computed or sent

  if (HAL_RTC_SetTime(&hrtc, &sTime, RTC_FORMAT_BIN) != HAL_OK) Error_Handler();
  if (HAL_RTC_SetDate(&hrtc, &sDate, RTC_FORMAT_BIN) != HAL_OK) Error_Handler();

  // Mark RTC as configured for future warm boots
  RTC->BKP0R = 0x32F2;
  */
}

static void MX_SPI2_Init(void)
{

  /* SPI2 parameter configuration*/
  hspi2.Instance = SPI2;
  hspi2.Init.Mode = SPI_MODE_MASTER;
  hspi2.Init.Direction = SPI_DIRECTION_2LINES;
  hspi2.Init.DataSize = SPI_DATASIZE_8BIT;
  hspi2.Init.CLKPolarity = SPI_POLARITY_HIGH;
  hspi2.Init.CLKPhase = SPI_PHASE_2EDGE;
  hspi2.Init.NSS = SPI_NSS_SOFT;
  hspi2.Init.BaudRatePrescaler = SPI_BAUDRATEPRESCALER_128;
  hspi2.Init.FirstBit = SPI_FIRSTBIT_MSB;
  hspi2.Init.TIMode = SPI_TIMODE_DISABLE;
  hspi2.Init.CRCCalculation = SPI_CRCCALCULATION_DISABLE;
  hspi2.Init.CRCPolynomial = 0x0;
  hspi2.Init.NSSPMode = SPI_NSS_PULSE_DISABLE;
  hspi2.Init.NSSPolarity = SPI_NSS_POLARITY_LOW;
  hspi2.Init.FifoThreshold = SPI_FIFO_THRESHOLD_01DATA;
  hspi2.Init.TxCRCInitializationPattern = SPI_CRC_INITIALIZATION_ALL_ZERO_PATTERN;
  hspi2.Init.RxCRCInitializationPattern = SPI_CRC_INITIALIZATION_ALL_ZERO_PATTERN;
  hspi2.Init.MasterSSIdleness = SPI_MASTER_SS_IDLENESS_00CYCLE;
  hspi2.Init.MasterInterDataIdleness = SPI_MASTER_INTERDATA_IDLENESS_00CYCLE;
  hspi2.Init.MasterReceiverAutoSusp = SPI_MASTER_RX_AUTOSUSP_DISABLE;
  hspi2.Init.MasterKeepIOState = SPI_MASTER_KEEP_IO_STATE_DISABLE;
  hspi2.Init.IOSwap = SPI_IO_SWAP_DISABLE;
  if (HAL_SPI_Init(&hspi2) != HAL_OK)
  {
    Error_Handler();
  }

}

static void MX_TIM2_Init(void)
{

  TIM_ClockConfigTypeDef sClockSourceConfig = {0};
  TIM_MasterConfigTypeDef sMasterConfig = {0};
  TIM_OC_InitTypeDef sConfigOC = {0};

  htim2.Instance = TIM2;
  htim2.Init.Prescaler = 199;
  htim2.Init.CounterMode = TIM_COUNTERMODE_UP;
  htim2.Init.Period = 99;
  htim2.Init.ClockDivision = TIM_CLOCKDIVISION_DIV1;
  htim2.Init.AutoReloadPreload = TIM_AUTORELOAD_PRELOAD_DISABLE;
  if (HAL_TIM_Base_Init(&htim2) != HAL_OK)
  {
    Error_Handler();
  }
  sClockSourceConfig.ClockSource = TIM_CLOCKSOURCE_INTERNAL;
  if (HAL_TIM_ConfigClockSource(&htim2, &sClockSourceConfig) != HAL_OK)
  {
    Error_Handler();
  }
  if (HAL_TIM_PWM_Init(&htim2) != HAL_OK)
  {
    Error_Handler();
  }
  sMasterConfig.MasterOutputTrigger = TIM_TRGO_RESET;
  sMasterConfig.MasterSlaveMode = TIM_MASTERSLAVEMODE_DISABLE;
  if (HAL_TIMEx_MasterConfigSynchronization(&htim2, &sMasterConfig) != HAL_OK)
  {
    Error_Handler();
  }
  sConfigOC.OCMode = TIM_OCMODE_PWM1;
  sConfigOC.Pulse = 0;
  sConfigOC.OCPolarity = TIM_OCPOLARITY_HIGH;
  sConfigOC.OCFastMode = TIM_OCFAST_DISABLE;
  if (HAL_TIM_PWM_ConfigChannel(&htim2, &sConfigOC, TIM_CHANNEL_2) != HAL_OK)
  {
    Error_Handler();
  }
  HAL_TIM_MspPostInit(&htim2);

}

static void MX_TIM3_Init(void)
{

  TIM_MasterConfigTypeDef sMasterConfig = {0};
  TIM_OC_InitTypeDef sConfigOC = {0};

  htim3.Instance = TIM3;
  htim3.Init.Prescaler = 0;
  htim3.Init.CounterMode = TIM_COUNTERMODE_UP;
  htim3.Init.Period = 65535;
  htim3.Init.ClockDivision = TIM_CLOCKDIVISION_DIV1;
  htim3.Init.AutoReloadPreload = TIM_AUTORELOAD_PRELOAD_ENABLE;
  if (HAL_TIM_OC_Init(&htim3) != HAL_OK)
  {
    Error_Handler();
  }
  sMasterConfig.MasterOutputTrigger = TIM_TRGO_RESET;
  sMasterConfig.MasterSlaveMode = TIM_MASTERSLAVEMODE_DISABLE;
  if (HAL_TIMEx_MasterConfigSynchronization(&htim3, &sMasterConfig) != HAL_OK)
  {
    Error_Handler();
  }
  sConfigOC.OCMode = TIM_OCMODE_ACTIVE;
  sConfigOC.Pulse = 0;
  sConfigOC.OCPolarity = TIM_OCPOLARITY_HIGH;
  sConfigOC.OCFastMode = TIM_OCFAST_DISABLE;
  if (HAL_TIM_OC_ConfigChannel(&htim3, &sConfigOC, TIM_CHANNEL_1) != HAL_OK)
  {
    Error_Handler();
  }
  __HAL_TIM_ENABLE_OCxPRELOAD(&htim3, TIM_CHANNEL_1);
  HAL_TIM_MspPostInit(&htim3);

}

static void MX_TIM4_Init(void)
{

  TIM_ClockConfigTypeDef sClockSourceConfig = {0};
  TIM_MasterConfigTypeDef sMasterConfig = {0};
  TIM_IC_InitTypeDef sConfigIC = {0};

  htim4.Instance = TIM4;
  htim4.Init.Prescaler = 0;
  htim4.Init.CounterMode = TIM_COUNTERMODE_UP;
  htim4.Init.Period = 65535;
  htim4.Init.ClockDivision = TIM_CLOCKDIVISION_DIV1;
  htim4.Init.AutoReloadPreload = TIM_AUTORELOAD_PRELOAD_DISABLE;
  if (HAL_TIM_Base_Init(&htim4) != HAL_OK)
  {
    Error_Handler();
  }
  sClockSourceConfig.ClockSource = TIM_CLOCKSOURCE_INTERNAL;
  if (HAL_TIM_ConfigClockSource(&htim4, &sClockSourceConfig) != HAL_OK)
  {
    Error_Handler();
  }
  if (HAL_TIM_IC_Init(&htim4) != HAL_OK)
  {
    Error_Handler();
  }
  sMasterConfig.MasterOutputTrigger = TIM_TRGO_RESET;
  sMasterConfig.MasterSlaveMode = TIM_MASTERSLAVEMODE_DISABLE;
  if (HAL_TIMEx_MasterConfigSynchronization(&htim4, &sMasterConfig) != HAL_OK)
  {
    Error_Handler();
  }
  sConfigIC.ICPolarity = TIM_INPUTCHANNELPOLARITY_RISING;
  sConfigIC.ICSelection = TIM_ICSELECTION_DIRECTTI;
  sConfigIC.ICPrescaler = TIM_ICPSC_DIV1;
  sConfigIC.ICFilter = 0;
  if (HAL_TIM_IC_ConfigChannel(&htim4, &sConfigIC, TIM_CHANNEL_1) != HAL_OK)
  {
    Error_Handler();
  }

}

static void MX_TIM6_Init(void)
{

  TIM_MasterConfigTypeDef sMasterConfig = {0};

  htim6.Instance = TIM6;
  htim6.Init.Prescaler = 0;
  htim6.Init.CounterMode = TIM_COUNTERMODE_UP;
  htim6.Init.Period = 65535;
  htim6.Init.AutoReloadPreload = TIM_AUTORELOAD_PRELOAD_DISABLE;
  if (HAL_TIM_Base_Init(&htim6) != HAL_OK)
  {
    Error_Handler();
  }
  sMasterConfig.MasterOutputTrigger = TIM_TRGO_UPDATE;
  sMasterConfig.MasterSlaveMode = TIM_MASTERSLAVEMODE_DISABLE;
  if (HAL_TIMEx_MasterConfigSynchronization(&htim6, &sMasterConfig) != HAL_OK)
  {
    Error_Handler();
  }

}

static void MX_TIM12_Init(void)
{

  TIM_ClockConfigTypeDef sClockSourceConfig = {0};
  TIM_MasterConfigTypeDef sMasterConfig = {0};
  TIM_OC_InitTypeDef sConfigOC = {0};

  htim12.Instance = TIM12;
  htim12.Init.Prescaler = 0;
  htim12.Init.CounterMode = TIM_COUNTERMODE_UP;
  htim12.Init.Period = 65535;
  htim12.Init.ClockDivision = TIM_CLOCKDIVISION_DIV1;
  htim12.Init.AutoReloadPreload = TIM_AUTORELOAD_PRELOAD_DISABLE;
  if (HAL_TIM_Base_Init(&htim12) != HAL_OK)
  {
    Error_Handler();
  }
  sClockSourceConfig.ClockSource = TIM_CLOCKSOURCE_INTERNAL;
  if (HAL_TIM_ConfigClockSource(&htim12, &sClockSourceConfig) != HAL_OK)
  {
    Error_Handler();
  }
  if (HAL_TIM_PWM_Init(&htim12) != HAL_OK)
  {
    Error_Handler();
  }
  sMasterConfig.MasterOutputTrigger = TIM_TRGO_RESET;
  sMasterConfig.MasterSlaveMode = TIM_MASTERSLAVEMODE_DISABLE;
  if (HAL_TIMEx_MasterConfigSynchronization(&htim12, &sMasterConfig) != HAL_OK)
  {
    Error_Handler();
  }
  sConfigOC.OCMode = TIM_OCMODE_PWM1;
  sConfigOC.Pulse = 0;
  sConfigOC.OCPolarity = TIM_OCPOLARITY_HIGH;
  sConfigOC.OCFastMode = TIM_OCFAST_DISABLE;
  if (HAL_TIM_PWM_ConfigChannel(&htim12, &sConfigOC, TIM_CHANNEL_1) != HAL_OK)
  {
    Error_Handler();
  }
  HAL_TIM_MspPostInit(&htim12);

}

static void MX_TIM14_Init(void)
{

  TIM_IC_InitTypeDef sConfigIC = {0};

  htim14.Instance = TIM14;
  htim14.Init.Prescaler = 0;
  htim14.Init.CounterMode = TIM_COUNTERMODE_UP;
  htim14.Init.Period = 65535;
  htim14.Init.ClockDivision = TIM_CLOCKDIVISION_DIV1;
  htim14.Init.AutoReloadPreload = TIM_AUTORELOAD_PRELOAD_DISABLE;
  if (HAL_TIM_Base_Init(&htim14) != HAL_OK)
  {
    Error_Handler();
  }
  if (HAL_TIM_IC_Init(&htim14) != HAL_OK)
  {
    Error_Handler();
  }
  sConfigIC.ICPolarity = TIM_INPUTCHANNELPOLARITY_RISING;
  sConfigIC.ICSelection = TIM_ICSELECTION_DIRECTTI;
  sConfigIC.ICPrescaler = TIM_ICPSC_DIV1;
  sConfigIC.ICFilter = 0;
  if (HAL_TIM_IC_ConfigChannel(&htim14, &sConfigIC, TIM_CHANNEL_1) != HAL_OK)
  {
    Error_Handler();
  }

}

static void MX_TIM15_Init(void)
{

  TIM_ClockConfigTypeDef sClockSourceConfig = {0};
  TIM_MasterConfigTypeDef sMasterConfig = {0};
  TIM_OC_InitTypeDef sConfigOC = {0};
  TIM_BreakDeadTimeConfigTypeDef sBreakDeadTimeConfig = {0};

  htim15.Instance = TIM15;
  htim15.Init.Prescaler = 0;
  htim15.Init.CounterMode = TIM_COUNTERMODE_UP;
  htim15.Init.Period = 65535;
  htim15.Init.ClockDivision = TIM_CLOCKDIVISION_DIV1;
  htim15.Init.RepetitionCounter = 0;
  htim15.Init.AutoReloadPreload = TIM_AUTORELOAD_PRELOAD_DISABLE;
  if (HAL_TIM_Base_Init(&htim15) != HAL_OK)
  {
    Error_Handler();
  }
  sClockSourceConfig.ClockSource = TIM_CLOCKSOURCE_INTERNAL;
  if (HAL_TIM_ConfigClockSource(&htim15, &sClockSourceConfig) != HAL_OK)
  {
    Error_Handler();
  }
  if (HAL_TIM_PWM_Init(&htim15) != HAL_OK)
  {
    Error_Handler();
  }
  sMasterConfig.MasterOutputTrigger = TIM_TRGO_RESET;
  sMasterConfig.MasterSlaveMode = TIM_MASTERSLAVEMODE_DISABLE;
  if (HAL_TIMEx_MasterConfigSynchronization(&htim15, &sMasterConfig) != HAL_OK)
  {
    Error_Handler();
  }
  sConfigOC.OCMode = TIM_OCMODE_PWM1;
  sConfigOC.Pulse = 0;
  sConfigOC.OCPolarity = TIM_OCPOLARITY_HIGH;
  sConfigOC.OCNPolarity = TIM_OCNPOLARITY_HIGH;
  sConfigOC.OCFastMode = TIM_OCFAST_DISABLE;
  sConfigOC.OCIdleState = TIM_OCIDLESTATE_RESET;
  sConfigOC.OCNIdleState = TIM_OCNIDLESTATE_RESET;
  if (HAL_TIM_PWM_ConfigChannel(&htim15, &sConfigOC, TIM_CHANNEL_1) != HAL_OK)
  {
    Error_Handler();
  }
  sBreakDeadTimeConfig.OffStateRunMode = TIM_OSSR_DISABLE;
  sBreakDeadTimeConfig.OffStateIDLEMode = TIM_OSSI_DISABLE;
  sBreakDeadTimeConfig.LockLevel = TIM_LOCKLEVEL_OFF;
  sBreakDeadTimeConfig.DeadTime = 0;
  sBreakDeadTimeConfig.BreakState = TIM_BREAK_DISABLE;
  sBreakDeadTimeConfig.BreakPolarity = TIM_BREAKPOLARITY_HIGH;
  sBreakDeadTimeConfig.BreakFilter = 0;
  sBreakDeadTimeConfig.AutomaticOutput = TIM_AUTOMATICOUTPUT_DISABLE;
  if (HAL_TIMEx_ConfigBreakDeadTime(&htim15, &sBreakDeadTimeConfig) != HAL_OK)
  {
    Error_Handler();
  }
  HAL_TIM_MspPostInit(&htim15);

}

static void MX_UART4_Init(void)
{

  huart4.Instance = UART4;
  huart4.Init.BaudRate = 115200;
  huart4.Init.WordLength = UART_WORDLENGTH_8B;
  huart4.Init.StopBits = UART_STOPBITS_1;
  huart4.Init.Parity = UART_PARITY_NONE;
  huart4.Init.Mode = UART_MODE_TX_RX;
  huart4.Init.HwFlowCtl = UART_HWCONTROL_NONE;
  huart4.Init.OverSampling = UART_OVERSAMPLING_16;
  huart4.Init.OneBitSampling = UART_ONE_BIT_SAMPLE_DISABLE;
  huart4.Init.ClockPrescaler = UART_PRESCALER_DIV1;
  huart4.AdvancedInit.AdvFeatureInit = UART_ADVFEATURE_NO_INIT;
  if (HAL_UART_Init(&huart4) != HAL_OK)
  {
    Error_Handler();
  }
  if (HAL_UARTEx_SetTxFifoThreshold(&huart4, UART_TXFIFO_THRESHOLD_1_8) != HAL_OK)
  {
    Error_Handler();
  }
  if (HAL_UARTEx_SetRxFifoThreshold(&huart4, UART_RXFIFO_THRESHOLD_1_8) != HAL_OK)
  {
    Error_Handler();
  }
  if (HAL_UARTEx_DisableFifoMode(&huart4) != HAL_OK)
  {
    Error_Handler();
  }

}

static void MX_UART5_Init(void)
{

  huart5.Instance = UART5;
  huart5.Init.BaudRate = 115200;
  huart5.Init.WordLength = UART_WORDLENGTH_8B;
  huart5.Init.StopBits = UART_STOPBITS_1;
  huart5.Init.Parity = UART_PARITY_NONE;
  huart5.Init.Mode = UART_MODE_TX_RX;
  huart5.Init.HwFlowCtl = UART_HWCONTROL_NONE;
  huart5.Init.OverSampling = UART_OVERSAMPLING_16;
  huart5.Init.OneBitSampling = UART_ONE_BIT_SAMPLE_DISABLE;
  huart5.Init.ClockPrescaler = UART_PRESCALER_DIV1;
  huart5.AdvancedInit.AdvFeatureInit = UART_ADVFEATURE_NO_INIT;
  if (HAL_UART_Init(&huart5) != HAL_OK)
  {
    Error_Handler();
  }
  if (HAL_UARTEx_SetTxFifoThreshold(&huart5, UART_TXFIFO_THRESHOLD_1_8) != HAL_OK)
  {
    Error_Handler();
  }
  if (HAL_UARTEx_SetRxFifoThreshold(&huart5, UART_RXFIFO_THRESHOLD_1_8) != HAL_OK)
  {
    Error_Handler();
  }
  if (HAL_UARTEx_DisableFifoMode(&huart5) != HAL_OK)
  {
    Error_Handler();
  }

}

static void MX_UART7_Init(void)
{

  huart7.Instance = UART7;
  huart7.Init.BaudRate   = 4800;
  huart7.Init.WordLength = UART_WORDLENGTH_9B;  // ← back to 8B
  huart7.Init.StopBits   = UART_STOPBITS_1;
  huart7.Init.Parity     = UART_PARITY_EVEN;    // ← back to NONE
  huart7.Init.Mode       = UART_MODE_TX_RX;
  huart7.Init.HwFlowCtl  = UART_HWCONTROL_NONE;
  huart7.Init.OverSampling       = UART_OVERSAMPLING_16;
  huart7.Init.OneBitSampling     = UART_ONE_BIT_SAMPLE_DISABLE;
  huart7.Init.ClockPrescaler     = UART_PRESCALER_DIV1;
  huart7.AdvancedInit.AdvFeatureInit   = UART_ADVFEATURE_RXINVERT_INIT | UART_ADVFEATURE_TXINVERT_INIT;
  huart7.AdvancedInit.TxPinLevelInvert = UART_ADVFEATURE_TXINV_ENABLE;
  huart7.AdvancedInit.RxPinLevelInvert = UART_ADVFEATURE_RXINV_ENABLE;
  if (HAL_UART_Init(&huart7) != HAL_OK)
  {
    Error_Handler();
  }
  if (HAL_UARTEx_SetTxFifoThreshold(&huart7, UART_TXFIFO_THRESHOLD_1_8) != HAL_OK)
  {
    Error_Handler();
  }
  if (HAL_UARTEx_SetRxFifoThreshold(&huart7, UART_RXFIFO_THRESHOLD_1_8) != HAL_OK)
  {
    Error_Handler();
  }
  if (HAL_UARTEx_DisableFifoMode(&huart7) != HAL_OK)
  {
    Error_Handler();
  }

}

static void MX_DMA_Init(void)
{

  /* DMA controller clock enable */
  __HAL_RCC_DMA1_CLK_ENABLE();

  /* DMA interrupt init */
  /* DMA1_Stream0_IRQn interrupt configuration */
  HAL_NVIC_SetPriority(DMA1_Stream0_IRQn, 0, 0);
  HAL_NVIC_EnableIRQ(DMA1_Stream0_IRQn);
  /* DMA1_Stream1_IRQn interrupt configuration */
  HAL_NVIC_SetPriority(DMA1_Stream1_IRQn, 0, 0);
  HAL_NVIC_EnableIRQ(DMA1_Stream1_IRQn);
  /* DMA1_Stream2_IRQn interrupt configuration */
  HAL_NVIC_SetPriority(DMA1_Stream2_IRQn, 0, 0);
  HAL_NVIC_EnableIRQ(DMA1_Stream2_IRQn);

}

static void MX_GPIO_Init(void)
{
  GPIO_InitTypeDef GPIO_InitStruct = {0};

  /* GPIO Ports Clock Enable */
  __HAL_RCC_GPIOE_CLK_ENABLE();
  __HAL_RCC_GPIOC_CLK_ENABLE();
  __HAL_RCC_GPIOH_CLK_ENABLE();
  __HAL_RCC_GPIOA_CLK_ENABLE();
  __HAL_RCC_GPIOB_CLK_ENABLE();
  __HAL_RCC_GPIOD_CLK_ENABLE();

  /*Configure GPIO pin Output Level */
  HAL_GPIO_WritePin(GPIOE, LED_1Hz_Pin|APSTATE_Pin|AMP_MUTE_Pin|AMPSTATE_Pin
                          |Tuner_RST_Pin, GPIO_PIN_RESET);

  /*Configure GPIO pin Output Level */
  HAL_GPIO_WritePin(GPIOC, U1LCD_CS_Pin|CD_MUTE_Pin|CDENABLE_Pin, GPIO_PIN_RESET);

  /*Configure GPIO pin Output Level */
  HAL_GPIO_WritePin(CDEJECT_GPIO_Port, CDEJECT_Pin, GPIO_PIN_RESET);

  /*Configure GPIO pin Output Level */
  HAL_GPIO_WritePin(GPIOD, GPIO_PIN_8|Fan_DOWN_Pin|Temp_UP_Pin|Temp_DOWN_Pin
                          |LCD_EN_Pin|LCD_ACMODE_Pin|LCD_RSMODE_Pin, GPIO_PIN_RESET);

  /*Configure GPIO pins : LED_1Hz_Pin APSTATE_Pin AMP_MUTE_Pin AMPSTATE_Pin
                           Tuner_RST_Pin */
  GPIO_InitStruct.Pin = LED_1Hz_Pin|APSTATE_Pin|AMP_MUTE_Pin|AMPSTATE_Pin
                          |Tuner_RST_Pin;
  GPIO_InitStruct.Mode = GPIO_MODE_OUTPUT_PP;
  GPIO_InitStruct.Pull = GPIO_NOPULL;
  GPIO_InitStruct.Speed = GPIO_SPEED_FREQ_LOW;
  HAL_GPIO_Init(GPIOE, &GPIO_InitStruct);

  /*Configure GPIO pins : U1LCD_CS_Pin CD_MUTE_Pin CDENABLE_Pin */
  GPIO_InitStruct.Pin = U1LCD_CS_Pin|CD_MUTE_Pin|CDENABLE_Pin;
  GPIO_InitStruct.Mode = GPIO_MODE_OUTPUT_PP;
  GPIO_InitStruct.Pull = GPIO_NOPULL;
  GPIO_InitStruct.Speed = GPIO_SPEED_FREQ_LOW;
  HAL_GPIO_Init(GPIOC, &GPIO_InitStruct);

  /*Configure GPIO pin : LMOUT_Pin */
  GPIO_InitStruct.Pin = LMOUT_Pin;
  GPIO_InitStruct.Mode = GPIO_MODE_ANALOG;
  GPIO_InitStruct.Pull = GPIO_NOPULL;
  HAL_GPIO_Init(LMOUT_GPIO_Port, &GPIO_InitStruct);

  /*Configure GPIO pin : CDEJECT_Pin */
  GPIO_InitStruct.Pin = CDEJECT_Pin;
  GPIO_InitStruct.Mode = GPIO_MODE_OUTPUT_PP;
  GPIO_InitStruct.Pull = GPIO_NOPULL;
  GPIO_InitStruct.Speed = GPIO_SPEED_FREQ_LOW;
  HAL_GPIO_Init(CDEJECT_GPIO_Port, &GPIO_InitStruct);

  /*Configure GPIO pins : PD8 Fan_DOWN_Pin Temp_UP_Pin Temp_DOWN_Pin
                           LCD_EN_Pin LCD_ACMODE_Pin LCD_RSMODE_Pin */
  GPIO_InitStruct.Pin = GPIO_PIN_8|Fan_DOWN_Pin|Temp_UP_Pin|Temp_DOWN_Pin
                          |LCD_EN_Pin|LCD_ACMODE_Pin|LCD_RSMODE_Pin;
  GPIO_InitStruct.Mode = GPIO_MODE_OUTPUT_PP;
  GPIO_InitStruct.Pull = GPIO_NOPULL;
  GPIO_InitStruct.Speed = GPIO_SPEED_FREQ_LOW;
  HAL_GPIO_Init(GPIOD, &GPIO_InitStruct);

  /*Configure GPIO pin : OUT25MHz_Pin */
  GPIO_InitStruct.Pin = OUT25MHz_Pin;
  GPIO_InitStruct.Mode = GPIO_MODE_AF_PP;
  GPIO_InitStruct.Pull = GPIO_NOPULL;
  GPIO_InitStruct.Speed = GPIO_SPEED_FREQ_LOW;
  GPIO_InitStruct.Alternate = GPIO_AF0_MCO;
  HAL_GPIO_Init(OUT25MHz_GPIO_Port, &GPIO_InitStruct);

  /*AnalogSwitch Config */
  HAL_SYSCFG_AnalogSwitchConfig(SYSCFG_SWITCH_PC3, SYSCFG_SWITCH_PC3_OPEN);

  /* USER CODE BEGIN MX_GPIO_Init_2 */
  GPIO_InitStruct.Pin = GPIO_PIN_3;
  GPIO_InitStruct.Mode = GPIO_MODE_OUTPUT_PP;
  GPIO_InitStruct.Pull = GPIO_NOPULL;
  GPIO_InitStruct.Speed = GPIO_SPEED_FREQ_LOW;
  HAL_GPIO_Init(GPIOE, &GPIO_InitStruct);

  HAL_GPIO_WritePin(GPIOE, GPIO_PIN_3, GPIO_PIN_SET);

  /* USER CODE END MX_GPIO_Init_2 */
}

/* USER CODE BEGIN 4 */

void Startup_Handshake(){
	uint32_t last_send = 0;

	Report_USB("Starting Handshake Sequence...");

	while(!HandshakeESP){
		// Ping the ESP32 every 1000ms (1 second)
		if (HAL_GetTick() - last_send > 1000) {
			Protocol_Send(&huart4, STM, CMD_HANDSHAKE, NULL, 0);
			last_send = HAL_GetTick();
			//Report_USB("Ping sent to ESP32...");
		}

		// Process any incoming packets
		Protocol_CheckFlag(&huart4, &huart5);
	}

	Report_USB("Handshake Complete!");
}

void Report_USB(const char* text) {
	//Simple function to report to usb easier
	char buf[128];
	size_t len = snprintf(buf, sizeof(buf), "%s\n", text);
	CDC_Transmit_FS((uint8_t*)buf, len);
	//HAL_Delay(20);
}

void I2C_Scan(I2C_HandleTypeDef *hi2c)
{
    char buf[64];
    uint8_t found = 0;

    Report_USB("--- I2C Scan Start ---");

    for (uint8_t addr = 0x08; addr <= 0xEF; addr += 2)
    {
        // HAL_I2C_IsDeviceReady attempts to contact the address
        // 1 trial, 10ms timeout
        if (HAL_I2C_IsDeviceReady(hi2c, addr, 3, 100) == HAL_OK)
        {
            snprintf(buf, sizeof(buf),
                     "Found: 0x%02X (7-bit: 0x%02X)",
                     addr, addr >> 1);
            Report_USB(buf);
            found++;
        }
    }

    if (found == 0)
    {
        Report_USB("No devices found.");
    }
    else
    {
        snprintf(buf, sizeof(buf), "Scan complete. %d device(s) found.", found);
        Report_USB(buf);
    }

    Report_USB("--- I2C Scan End ---");
}

void HAL_RTC_AlarmAEventCallback(RTC_HandleTypeDef *hrtc) {
    minuteChanged = 1;
}

void HAL_FDCAN_RxFifo0Callback(FDCAN_HandleTypeDef *hfdcan1, uint32_t RxFifo0ITs){
	/* - This function is active when an interrupt is fired   -
	 * - Reads the incoming CAN Frame and retransmits on CAN2 - */
	//Report_USB("Frame RX");
	if (hfdcan1->Instance != FDCAN1){
	    return;
	    //if FDCAN2 calls the fifo then it will not run the code.
	}
	if((RxFifo0ITs & FDCAN_IT_RX_FIFO0_NEW_MESSAGE) != RESET){
		can_sent_flag = 1;

		FDCAN_RxHeaderTypeDef rxHeader;
		uint8_t	rxData[64];

		//Read the incoming message
		HAL_FDCAN_GetRxMessage(
				hfdcan1,
				FDCAN_RX_FIFO0,
				&rxHeader,
				rxData);

		//Prepare Tx Header (Copy of RX)
		FDCAN_TxHeaderTypeDef txHeader = {
				.Identifier				= rxHeader.Identifier,
				.IdType					= rxHeader.IdType,
				.TxFrameType 			= rxHeader.RxFrameType,
				.DataLength				= rxHeader.DataLength,
				.ErrorStateIndicator	= rxHeader.ErrorStateIndicator,
				.BitRateSwitch			= rxHeader.BitRateSwitch,
				.FDFormat				= rxHeader.FDFormat,
				.TxEventFifoControl		= FDCAN_NO_TX_EVENTS,
				.MessageMarker			= 0
		};

		if (HAL_FDCAN_GetTxFifoFreeLevel(&hfdcan2) > 0){
			//retransmit the can frame
			HAL_FDCAN_AddMessageToTxFifoQ(&hfdcan2, &txHeader, rxData);
			can_sent_flag = 1;
			can_sent_counter++;
		}
		else{
			//report an error if it fails to transmit
			canError++;
			can_drop_counter++;
		}

	}
}

void HAL_UART_RxCpltCallback(UART_HandleTypeDef *huart)
{
    if (huart->Instance == UART4)
        PACKET_READY4 = 1;

    else if (huart->Instance == UART5){
        PACKET_READY5 = 1;
    }

    else if (huart->Instance == UART7)
    {
        //uart7RxCount++;
        ClimatePacketReady = 1;   // always exactly 5 bytes
    }
}

void HAL_UARTEx_RxEventCallback(UART_HandleTypeDef *huart, uint16_t Size)
{
    if (huart->Instance == UART4)
    {
        if (Size == RX_PACKET_LEN)
        {
            // Full packet received
            PACKET_READY4 = 1;
        }
        else
        {
            // Wrong size — partial packet, resync
            //char dbg[32];
            //snprintf(dbg, sizeof(dbg), "UART4 bad size: %d", Size);
            //Report_USB(dbg);
            HAL_UARTEx_ReceiveToIdle_DMA(&huart4, RxBuf4, RX_PACKET_LEN);
        }
    }

    else if (huart->Instance == UART5)
    {
        if (Size == RX_PACKET_LEN)
        {
        	uart5RxCount++;
            PACKET_READY5 = 1;
        }
        else
        {
            HAL_UARTEx_ReceiveToIdle_DMA(&huart5, RxBuf5, RX_PACKET_LEN);
        }
    }

    else if (huart->Instance == UART7)
        {
    	    if (Size == AC_PACKET_LEN)
            {
                // Full packet received
                ClimatePacketReady = 1;
                //Report_USB("AC PACKET Received");
            }
            else
            {
            	HAL_UARTEx_ReceiveToIdle_DMA(&huart7, ClimateBuf, AC_PACKET_LEN);    // ✅
                //Report_USB("AC PACKET REARMED");
            }
            //Report_USB("AC PACKET");
        }
    //Report_USB("DMA Check Done");
}

void HAL_UART_ErrorCallback(UART_HandleTypeDef *huart)
{

    // Decode the specific error
    //if (error_code & HAL_UART_ERROR_PE)  Report_USB("UART ERROR: Parity Error (PE)");
    //if (error_code & HAL_UART_ERROR_NE)  Report_USB("UART ERROR: Noise Error (NE)");
    //if (error_code & HAL_UART_ERROR_FE)  Report_USB("UART ERROR: Framing Error (FE)");
    //if (error_code & HAL_UART_ERROR_ORE) Report_USB("UART ERROR: Overrun Error (ORE)");
    //if (error_code & HAL_UART_ERROR_DMA) Report_USB("UART ERROR: DMA Transfer Error");

    // Forcefully restart the listener
    if (huart->Instance == UART4) {
        HAL_UART_AbortReceive(huart);
        HAL_UARTEx_ReceiveToIdle_DMA(huart, RxBuf4, RX_PACKET_LEN);
    }
    else if (huart->Instance == UART5) {
        HAL_UART_AbortReceive(huart);
        HAL_UARTEx_ReceiveToIdle_DMA(huart, RxBuf5, RX_PACKET_LEN);
    }

    else if (huart->Instance == UART7) {
	    uart7ErrorCode = huart->ErrorCode;
	    uart7ErrorFlag = 1;
        // Report exactly what error is occurring
        //char dbg[48];
        //snprintf(dbg, sizeof(dbg), "UART7 ERR: 0x%08lX", huart->ErrorCode);
        HAL_UART_AbortReceive(huart);
        HAL_UARTEx_ReceiveToIdle_DMA(&huart7, ClimateBuf, AC_PACKET_LEN);
        //Report_USB("UART7 DMA Restarted.");
    }
}

/* USER CODE END 4 */

 /* MPU Configuration */

void MPU_Config(void)
{
  MPU_Region_InitTypeDef MPU_InitStruct = {0};

  /* Disables the MPU */
  HAL_MPU_Disable();

  /** Initializes and configures the Region and the memory to be protected
  */
  MPU_InitStruct.Enable = MPU_REGION_ENABLE;
  MPU_InitStruct.Number = MPU_REGION_NUMBER0;
  MPU_InitStruct.BaseAddress = 0x0;
  MPU_InitStruct.Size = MPU_REGION_SIZE_4GB;
  MPU_InitStruct.SubRegionDisable = 0x87;
  MPU_InitStruct.TypeExtField = MPU_TEX_LEVEL0;
  MPU_InitStruct.AccessPermission = MPU_REGION_NO_ACCESS;
  MPU_InitStruct.DisableExec = MPU_INSTRUCTION_ACCESS_DISABLE;
  MPU_InitStruct.IsShareable = MPU_ACCESS_SHAREABLE;
  MPU_InitStruct.IsCacheable = MPU_ACCESS_NOT_CACHEABLE;
  MPU_InitStruct.IsBufferable = MPU_ACCESS_NOT_BUFFERABLE;

  HAL_MPU_ConfigRegion(&MPU_InitStruct);
  /* Enables the MPU */
  HAL_MPU_Enable(MPU_PRIVILEGED_DEFAULT);

}

void Error_Handler(void)
{
  __disable_irq();
  while (1)
  {
  }
}
